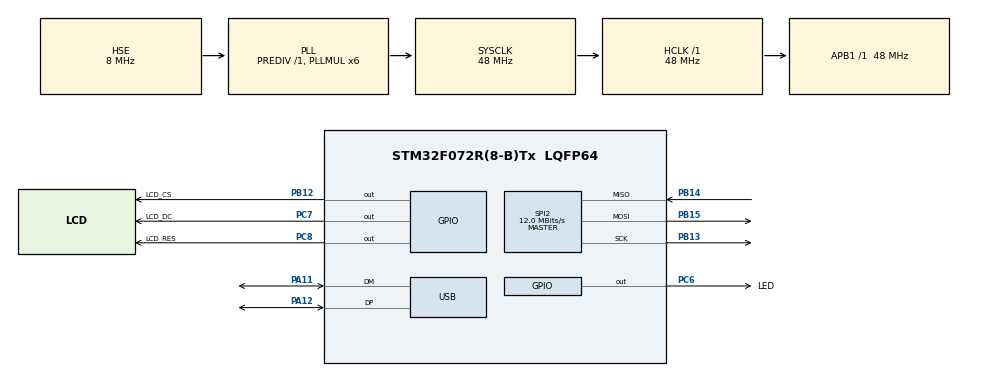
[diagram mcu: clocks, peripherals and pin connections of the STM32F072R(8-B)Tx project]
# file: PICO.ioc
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Mcu.Family=STM32F0
Mcu.Name=STM32F072R(8-B)Tx
Mcu.Package=LQFP64
PA11.Mode=Device
PA11.Signal=USB_DM
PA12.Mode=Device
PA12.Signal=USB_DP
PA13.Mode=Serial_Wire
PA13.Signal=SYS_SWDIO
PA14.Mode=Serial_Wire
PA14.Signal=SYS_SWCLK
PB12.GPIO_Label=LCD_CS
PB12.GPIO_Speed=GPIO_SPEED_FREQ_HIGH
PB12.PinState=GPIO_PIN_RESET
PB12.Signal=GPIO_Output
PB13.Mode=Full_Duplex_Master
PB13.Signal=SPI2_SCK
PB14.Mode=Full_Duplex_Master
PB14.Signal=SPI2_MISO
PB15.Mode=Full_Duplex_Master
PB15.Signal=SPI2_MOSI
PC14-OSC32_IN.Mode=LSE-External-Oscillator
PC14-OSC32_IN.Signal=RCC_OSC32_IN
PC15-OSC32_OUT.Mode=LSE-External-Oscillator
PC15-OSC32_OUT.Signal=RCC_OSC32_OUT
PC6.GPIO_Label=LED
PC6.GPIO_Speed=GPIO_SPEED_FREQ_HIGH
PC6.PinState=GPIO_PIN_RESET
PC6.Signal=GPIO_Output
PC7.GPIO_Label=LCD_DC
PC7.GPIO_Speed=GPIO_SPEED_FREQ_HIGH
PC7.PinState=GPIO_PIN_RESET
PC7.Signal=GPIO_Output
PC8.GPIO_Label=LCD_RES
PC8.GPIO_Speed=GPIO_SPEED_FREQ_HIGH
PC8.PinState=GPIO_PIN_RESET
PC8.Signal=GPIO_Output
PF0-OSC_IN.Mode=HSE-External-Oscillator
PF0-OSC_IN.Signal=RCC_OSC_IN
PF1-OSC_OUT.Mode=HSE-External-Oscillator
PF1-OSC_OUT.Signal=RCC_OSC_OUT
ProjectManager.HeapSize=0x200
ProjectManager.StackSize=0x400
ProjectManager.TargetToolchain=MDK-ARM V5.32
RCC.AHBFreq_Value=48000000
RCC.APB1Freq_Value=48000000
RCC.APB1TimFreq_Value=48000000
RCC.HCLKFreq_Value=48000000
RCC.PLLMUL=RCC_PLL_MUL6
RCC.PLLSourceVirtual=RCC_PLLSOURCE_HSE
RCC.SYSCLKFreq_VALUE=48000000
RCC.SYSCLKSource=RCC_SYSCLKSOURCE_PLLCLK
SPI2.BaudRatePrescaler=SPI_BAUDRATEPRESCALER_4
SPI2.CalculateBaudRate=12.0 MBits/s
SPI2.DataSize=SPI_DATASIZE_8BIT
SPI2.Direction=SPI_DIRECTION_2LINES
SPI2.Mode=SPI_MODE_MASTER
SPI2.VirtualType=VM_MASTER
board=custom

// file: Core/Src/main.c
/* USER CODE BEGIN Header */
/**
  ******************************************************************************
  * @file           : main.c
  * @brief          : Main program body
  ******************************************************************************
  * @attention
  *
  * Copyright (c) 2025 STMicroelectronics.
  * All rights reserved.
  *
  * This software is licensed under terms that can be found in the LICENSE file
  * in the root directory of this software component.
  * If no LICENSE file comes with this software, it is provided AS-IS.
  *
  ******************************************************************************
  */
/* USER CODE END Header */
#include "main.h"
#include "spi.h"
#include "usb.h"
#include "gpio.h"

/* USER CODE BEGIN Includes */
#include "lcd.h"
/* USER CODE END Includes */

void SystemClock_Config(void);

int main(void)
{

  /* MCU Configuration--------------------------------------------------------*/

  /* Reset of all peripherals, Initializes the Flash interface and the Systick. */
  HAL_Init();

  /* Configure the system clock */
  SystemClock_Config();

  /* Initialize all configured peripherals */
  MX_GPIO_Init();
  MX_SPI2_Init();
  MX_USB_PCD_Init();
  /* USER CODE BEGIN 2 */
  LCD_Init();
  LCD_Clear(0xFFFF);
  /* USER CODE END 2 */

  /* Infinite loop */
  while (1)
  {

  }
}

void SystemClock_Config(void)
{
  RCC_OscInitTypeDef RCC_OscInitStruct = {0};
  RCC_ClkInitTypeDef RCC_ClkInitStruct = {0};
  RCC_PeriphCLKInitTypeDef PeriphClkInit = {0};

  /** Initializes the RCC Oscillators according to the specified parameters
  * in the RCC_OscInitTypeDef structure.
  */
  RCC_OscInitStruct.OscillatorType = RCC_OSCILLATORTYPE_HSI48|RCC_OSCILLATORTYPE_HSE;
  RCC_OscInitStruct.HSEState = RCC_HSE_ON;
  RCC_OscInitStruct.HSI48State = RCC_HSI48_ON;
  RCC_OscInitStruct.PLL.PLLState = RCC_PLL_ON;
  RCC_OscInitStruct.PLL.PLLSource = RCC_PLLSOURCE_HSE;
  RCC_OscInitStruct.PLL.PLLMUL = RCC_PLL_MUL6;
  RCC_OscInitStruct.PLL.PREDIV = RCC_PREDIV_DIV1;
  if (HAL_RCC_OscConfig(&RCC_OscInitStruct) != HAL_OK)
  {
    Error_Handler();
  }

  /** Initializes the CPU, AHB and APB buses clocks
  */
  RCC_ClkInitStruct.ClockType = RCC_CLOCKTYPE_HCLK|RCC_CLOCKTYPE_SYSCLK
                              |RCC_CLOCKTYPE_PCLK1;
  RCC_ClkInitStruct.SYSCLKSource = RCC_SYSCLKSOURCE_PLLCLK;
  RCC_ClkInitStruct.AHBCLKDivider = RCC_SYSCLK_DIV1;
  RCC_ClkInitStruct.APB1CLKDivider = RCC_HCLK_DIV1;

  if (HAL_RCC_ClockConfig(&RCC_ClkInitStruct, FLASH_LATENCY_1) != HAL_OK)
  {
    Error_Handler();
  }
  PeriphClkInit.PeriphClockSelection = RCC_PERIPHCLK_USB;
  PeriphClkInit.UsbClockSelection = RCC_USBCLKSOURCE_HSI48;

  if (HAL_RCCEx_PeriphCLKConfig(&PeriphClkInit) != HAL_OK)
  {
    Error_Handler();
  }
}

void Error_Handler(void)
{
  __disable_irq();
  while (1)
  {
  }
}
